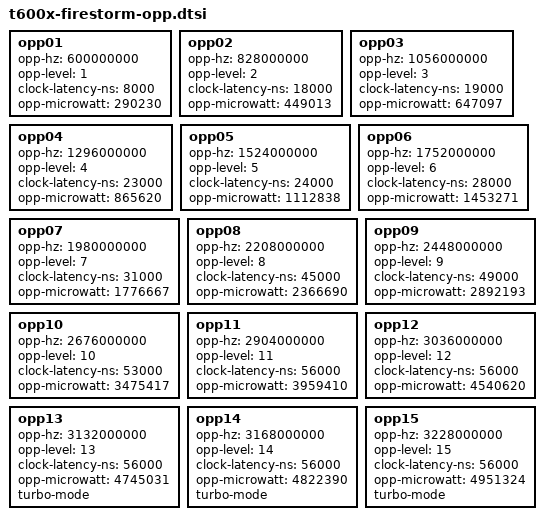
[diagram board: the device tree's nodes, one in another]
// SPDX-License-Identifier: GPL-2.0+ OR MIT
/*
 * Operating points for Apple T600x Firestorm (P-cluster) cores.
 *
 * Copyright The Asahi Linux Contributors
 */

		opp01 {
			opp-hz = /bits/ 64 <600000000>;
			opp-level = <1>;
			clock-latency-ns = <8000>;
			opp-microwatt = <290230>;
		};
		opp02 {
			opp-hz = /bits/ 64 <828000000>;
			opp-level = <2>;
			clock-latency-ns = <18000>;
			opp-microwatt = <449013>;
		};
		opp03 {
			opp-hz = /bits/ 64 <1056000000>;
			opp-level = <3>;
			clock-latency-ns = <19000>;
			opp-microwatt = <647097>;
		};
		opp04 {
			opp-hz = /bits/ 64 <1296000000>;
			opp-level = <4>;
			clock-latency-ns = <23000>;
			opp-microwatt = <865620>;
		};
		opp05 {
			opp-hz = /bits/ 64 <1524000000>;
			opp-level = <5>;
			clock-latency-ns = <24000>;
			opp-microwatt = <1112838>;
		};
		opp06 {
			opp-hz = /bits/ 64 <1752000000>;
			opp-level = <6>;
			clock-latency-ns = <28000>;
			opp-microwatt = <1453271>;
		};
		opp07 {
			opp-hz = /bits/ 64 <1980000000>;
			opp-level = <7>;
			clock-latency-ns = <31000>;
			opp-microwatt = <1776667>;
		};
		opp08 {
			opp-hz = /bits/ 64 <2208000000>;
			opp-level = <8>;
			clock-latency-ns = <45000>;
			opp-microwatt = <2366690>;
		};
		opp09 {
			opp-hz = /bits/ 64 <2448000000>;
			opp-level = <9>;
			clock-latency-ns = <49000>;
			opp-microwatt = <2892193>;
		};
		opp10 {
			opp-hz = /bits/ 64 <2676000000>;
			opp-level = <10>;
			clock-latency-ns = <53000>;
			opp-microwatt = <3475417>;
		};
		opp11 {
			opp-hz = /bits/ 64 <2904000000>;
			opp-level = <11>;
			clock-latency-ns = <56000>;
			opp-microwatt = <3959410>;
		};
		opp12 {
			opp-hz = /bits/ 64 <3036000000>;
			opp-level = <12>;
			clock-latency-ns = <56000>;
			opp-microwatt = <4540620>;
		};
		opp13 {
			opp-hz = /bits/ 64 <3132000000>;
			opp-level = <13>;
			clock-latency-ns = <56000>;
			opp-microwatt = <4745031>;
			turbo-mode;
		};
		opp14 {
			opp-hz = /bits/ 64 <3168000000>;
			opp-level = <14>;
			clock-latency-ns = <56000>;
			opp-microwatt = <4822390>;
			turbo-mode;
		};
		opp15 {
			opp-hz = /bits/ 64 <3228000000>;
			opp-level = <15>;
			clock-latency-ns = <56000>;
			opp-microwatt = <4951324>;
			turbo-mode;
		};
